# STM32G0B0VET6 register map
File version: 1.0
Registers are 32-bit, access not given, reset 0x0 unless marked. A register's access mark holds for its fields unless they carry their own. Offsets are from the block's base; [hi:lo] are bit positions; {n}, {i} and the like mark numbered series; 'fields as' and 'values as' point back to an identical list.

## DBG
Base 0x40015800
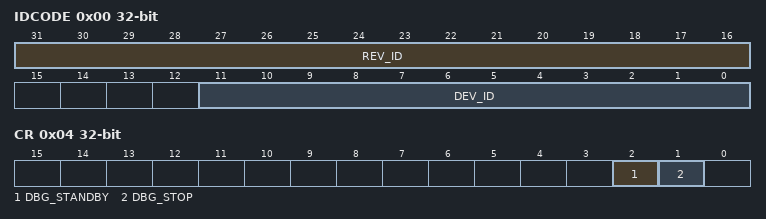
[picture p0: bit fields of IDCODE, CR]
0x00 IDCODE
  [31:16] REV_ID, [11:0] DEV_ID
0x04 CR
  [2] DBG_STANDBY, [1] DBG_STOP
0x08 APBFZ1
0x0C APBFZ2

## DMA1
Base 0x40020000
Same registers: DMA2 0x40020400
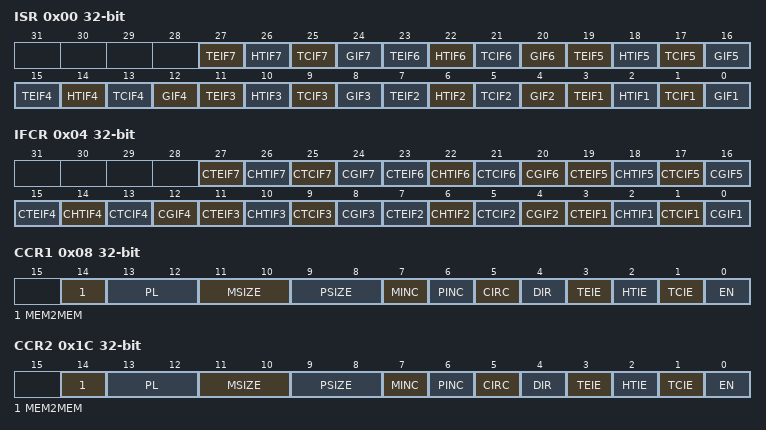
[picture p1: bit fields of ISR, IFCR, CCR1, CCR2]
0x00 ISR
  [4n-1] TEIF{n} (n=1..7), [4n-2] HTIF{n} (n=1..7), [4n-3] TCIF{n} (n=1..7), [4n-4] GIF{n} (n=1..7)
0x04 IFCR
  [4n-1] CTEIF{n} (n=1..7), [4n-2] CHTIF{n} (n=1..7), [4n-3] CTCIF{n} (n=1..7), [4n-4] CGIF{n} (n=1..7)
0x08 CCR1
  [14] MEM2MEM, [13:12] PL, [11:10] MSIZE, [9:8] PSIZE, [7] MINC, [6] PINC, [5] CIRC, [4] DIR, [3] TEIE, [2] HTIE, [1] TCIE, [0] EN
0x0C CNDTR1
  [15:0] NDT
0x10 CPAR1
  [31:0] PA
{0x0+0x14*i} CMAR{i} (i=1..7)
  [31:0] MA
0x1C CCR2
  fields as CCR1
0x20 CNDTR2
  [15:0] NDT
0x24 CPAR2
  [31:0] PA
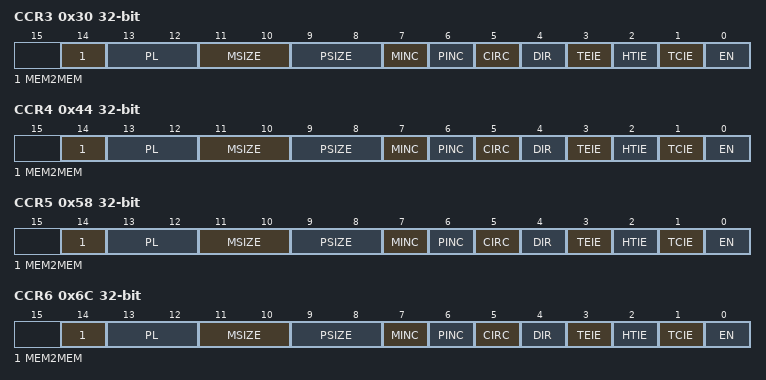
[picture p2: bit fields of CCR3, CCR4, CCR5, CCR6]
0x30 CCR3
  fields as CCR1
0x34 CNDTR3
  [15:0] NDT
0x38 CPAR3
  [31:0] PA
0x44 CCR4
  fields as CCR1
0x48 CNDTR4
  [15:0] NDT
0x4C CPAR4
  [31:0] PA
0x58 CCR5
  fields as CCR1
0x5C CNDTR5
  [15:0] NDT
0x60 CPAR5
  [31:0] PA
0x6C CCR6
  fields as CCR1
0x70 CNDTR6
  [15:0] NDT
0x74 CPAR6
  [31:0] PA
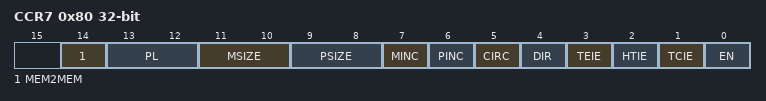
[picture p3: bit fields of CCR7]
0x80 CCR7
  fields as CCR1
0x84 CNDTR7
  [15:0] NDT
0x88 CPAR7
  [31:0] PA

## DMAMUX1
Base 0x40020800
0x00 CCR0
0x04 CCR1
0x08 CCR2
0x0C CCR3
{0x0+4i} CCR{i} (i=4..9)
0x28 CCR0
0x2C CCR1
0x80 CCRs
0x100 CCR0
0x104 CCR1
0x108 CCR2
0x10C CCR3
0x140 CCRs

## RCC
Base 0x40021000
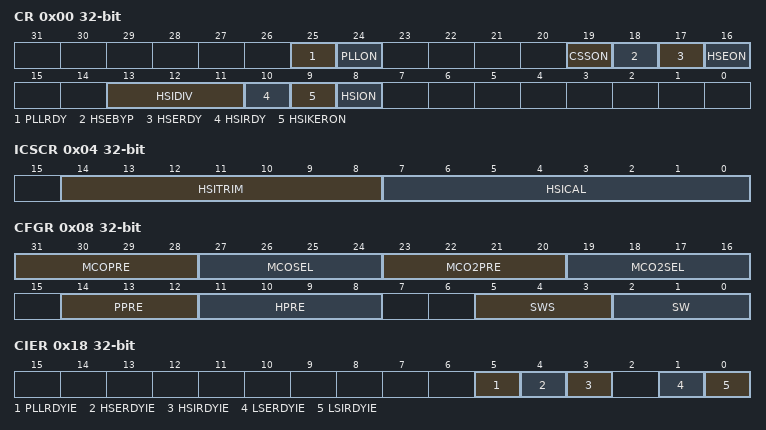
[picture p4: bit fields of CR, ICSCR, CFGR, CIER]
0x00 CR
  [25] PLLRDY, [24] PLLON, [19] CSSON, [18] HSEBYP, [17] HSERDY, [16] HSEON, [13:11] HSIDIV, [10] HSIRDY, [9] HSIKERON, [8] HSION
0x04 ICSCR
  [14:8] HSITRIM, [7:0] HSICAL
0x08 CFGR
  [31:28] MCOPRE, [27:24] MCOSEL, [23:20] MCO2PRE, [19:16] MCO2SEL, [14:12] PPRE, [11:8] HPRE, [5:3] SWS, [2:0] SW
0x0C PLLCFGR
  [31:29] PLLR, [28] PLLREN, [27:25] PLLQ, [24] PLLQEN, [21:17] PLLP, [16] PLLPEN, [14:8] PLLN, [6:4] PLLM, [1] PLLSRC_HSI, [1:0] PLLSRC_HSE
0x14 CRRCR
0x18 CIER
  [5] PLLRDYIE, [4] HSERDYIE, [3] HSIRDYIE, [1] LSERDYIE, [0] LSIRDYIE
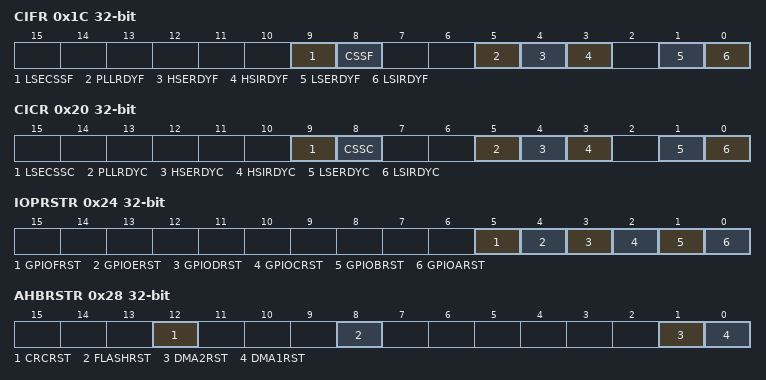
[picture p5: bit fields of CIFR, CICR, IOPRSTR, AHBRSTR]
0x1C CIFR
  [9] LSECSSF, [8] CSSF, [5] PLLRDYF, [4] HSERDYF, [3] HSIRDYF, [1] LSERDYF, [0] LSIRDYF
0x20 CICR
  [9] LSECSSC, [8] CSSC, [5] PLLRDYC, [4] HSERDYC, [3] HSIRDYC, [1] LSERDYC, [0] LSIRDYC
0x24 IOPRSTR
  [5] GPIOFRST, [4] GPIOERST, [3] GPIODRST, [2] GPIOCRST, [1] GPIOBRST, [0] GPIOARST
0x28 AHBRSTR
  [12] CRCRST, [8] FLASHRST, [1] DMA2RST, [0] DMA1RST
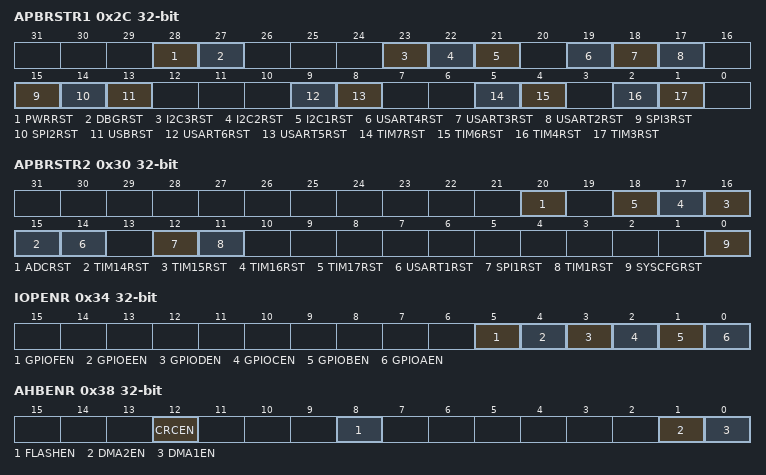
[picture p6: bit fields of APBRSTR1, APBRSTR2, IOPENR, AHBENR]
0x2C APBRSTR1
  [28] PWRRST, [27] DBGRST, [23] I2C3RST, [22] I2C2RST, [21] I2C1RST, [19] USART4RST, [18] USART3RST, [17] USART2RST, [15] SPI3RST, [14] SPI2RST, [13] USBRST, [9] USART6RST, [8] USART5RST, [5] TIM7RST, [4] TIM6RST, [2] TIM4RST, [1] TIM3RST
0x30 APBRSTR2
  [20] ADCRST, [n+1] TIM{n}RST (n=14..17), [14] USART1RST, [12] SPI1RST, [11] TIM1RST, [0] SYSCFGRST
0x34 IOPENR
  [5] GPIOFEN, [4] GPIOEEN, [3] GPIODEN, [2] GPIOCEN, [1] GPIOBEN, [0] GPIOAEN
0x38 AHBENR
  [12] CRCEN, [8] FLASHEN, [1] DMA2EN, [0] DMA1EN
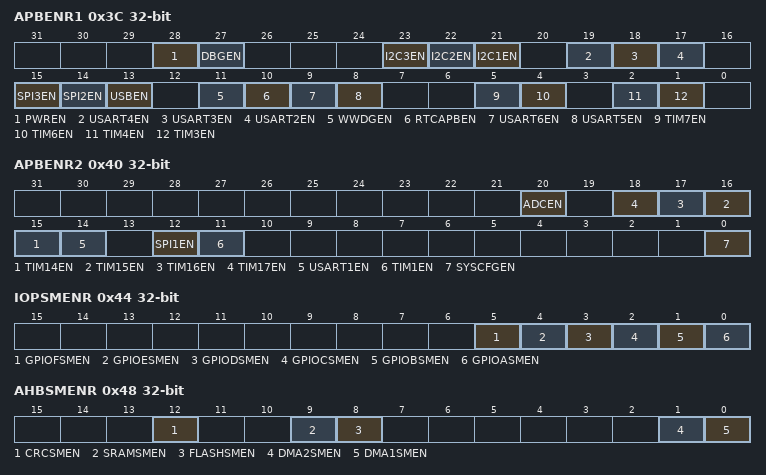
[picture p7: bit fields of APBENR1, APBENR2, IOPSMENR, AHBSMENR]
0x3C APBENR1
  [28] PWREN, [27] DBGEN, [23] I2C3EN, [22] I2C2EN, [21] I2C1EN, [19] USART4EN, [18] USART3EN, [17] USART2EN, [15] SPI3EN, [14] SPI2EN, [13] USBEN, [11] WWDGEN, [10] RTCAPBEN, [9] USART6EN, [8] USART5EN, [5] TIM7EN, [4] TIM6EN, [2] TIM4EN, [1] TIM3EN
0x40 APBENR2
  [20] ADCEN, [n+1] TIM{n}EN (n=14..17), [14] USART1EN, [12] SPI1EN, [11] TIM1EN, [0] SYSCFGEN
0x44 IOPSMENR
  [5] GPIOFSMEN, [4] GPIOESMEN, [3] GPIODSMEN, [2] GPIOCSMEN, [1] GPIOBSMEN, [0] GPIOASMEN
0x48 AHBSMENR
  [12] CRCSMEN, [9] SRAMSMEN, [8] FLASHSMEN, [1] DMA2SMEN, [0] DMA1SMEN
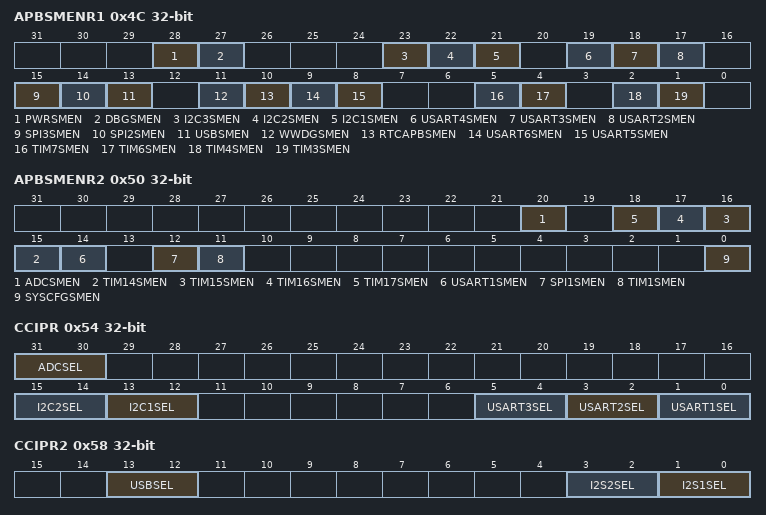
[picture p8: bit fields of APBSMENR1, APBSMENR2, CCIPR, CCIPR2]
0x4C APBSMENR1
  [28] PWRSMEN, [27] DBGSMEN, [23] I2C3SMEN, [22] I2C2SMEN, [21] I2C1SMEN, [19] USART4SMEN, [18] USART3SMEN, [17] USART2SMEN, [15] SPI3SMEN, [14] SPI2SMEN, [13] USBSMEN, [11] WWDGSMEN, [10] RTCAPBSMEN, [9] USART6SMEN, [8] USART5SMEN, [5] TIM7SMEN, [4] TIM6SMEN, [2] TIM4SMEN, [1] TIM3SMEN
0x50 APBSMENR2
  [20] ADCSMEN, [n+1] TIM{n}SMEN (n=14..17), [14] USART1SMEN, [12] SPI1SMEN, [11] TIM1SMEN, [0] SYSCFGSMEN
0x54 CCIPR
  [31:30] ADCSEL, [15:14] I2C2SEL, [13:12] I2C1SEL, [5:4] USART3SEL, [3:2] USART2SEL, [1:0] USART1SEL
0x58 CCIPR2
  [13:12] USBSEL, [3:2] I2S2SEL, [1:0] I2S1SEL
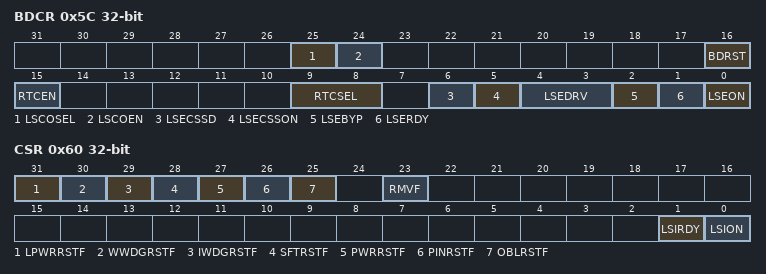
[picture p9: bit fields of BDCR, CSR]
0x5C BDCR
  [25] LSCOSEL, [24] LSCOEN, [16] BDRST, [15] RTCEN, [9:8] RTCSEL, [6] LSECSSD, [5] LSECSSON, [4:3] LSEDRV, [2] LSEBYP, [1] LSERDY, [0] LSEON
0x60 CSR
  [31] LPWRRSTF, [30] WWDGRSTF, [29] IWDGRSTF, [28] SFTRSTF, [27] PWRRSTF, [26] PINRSTF, [25] OBLRSTF, [23] RMVF, [1] LSIRDY, [0] LSION

## EXTI
Base 0x40021800
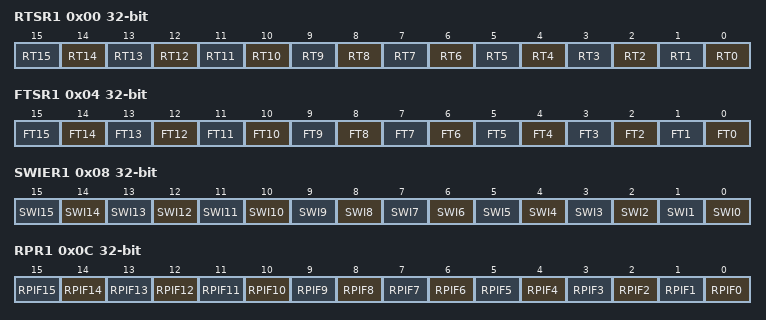
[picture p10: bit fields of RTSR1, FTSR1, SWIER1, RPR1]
0x00 RTSR1
  [n] RT{n} (n=0..15)
0x04 FTSR1
  [n] FT{n} (n=0..15)
0x08 SWIER1
  [n] SWI{n} (n=0..15)
0x0C RPR1
  [n] RPIF{n} (n=0..15)
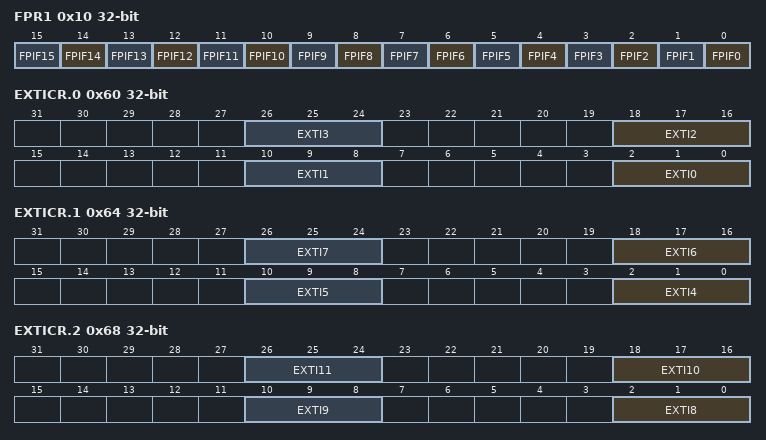
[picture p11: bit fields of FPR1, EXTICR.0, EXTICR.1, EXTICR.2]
0x10 FPR1
  [n] FPIF{n} (n=0..15)
0x60 EXTICR.0
  [8n+2:8n] EXTI{n} (n=0..3)
0x64 EXTICR.1
  [8n-30:8n-32] EXTI{n} (n=4..7)
0x68 EXTICR.2
  [8n-62:8n-64] EXTI{n} (n=8..11)
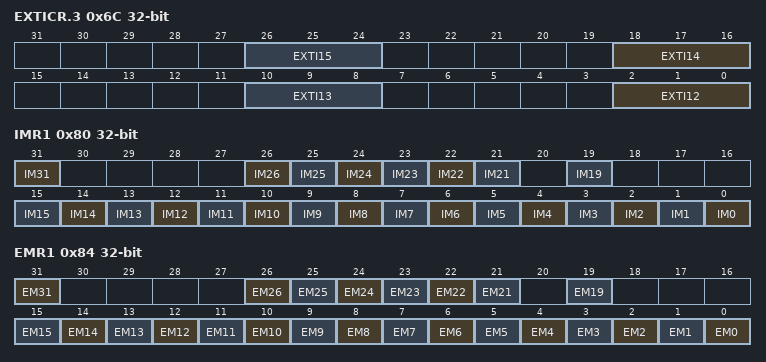
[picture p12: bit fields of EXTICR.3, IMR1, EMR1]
0x6C EXTICR.3
  [8n-94:8n-96] EXTI{n} (n=12..15)
0x80 IMR1
  [31] IM31, [n] IM{n} (n=21..26), [19] IM19, [n] IM{n} (n=0..15)
0x84 EMR1
  [31] EM31, [n] EM{n} (n=21..26), [19] EM19, [n] EM{n} (n=0..15)
0x90 IMR2
  [4] IM36, [4:0] IM
0x94 EMR2
  [4] EM36

## FLASH
Base 0x40022000
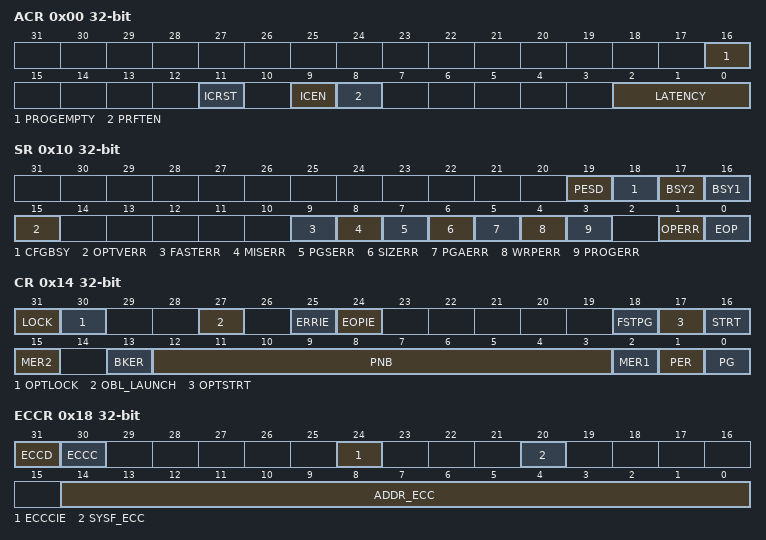
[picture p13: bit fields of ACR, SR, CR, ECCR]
0x00 ACR
  [16] PROGEMPTY, [11] ICRST, [9] ICEN, [8] PRFTEN, [2:0] LATENCY
0x08 KEYR
0x0C OPTKEYR
0x10 SR
  [19] PESD, [18] CFGBSY, [17] BSY2, [16] BSY1, [15] OPTVERR, [9] FASTERR, [8] MISERR, [7] PGSERR, [6] SIZERR, [5] PGAERR, [4] WRPERR, [3] PROGERR, [1] OPERR, [0] EOP
0x14 CR
  [31] LOCK, [30] OPTLOCK, [27] OBL_LAUNCH, [25] ERRIE, [24] EOPIE, [18] FSTPG, [17] OPTSTRT, [16] STRT, [15] MER2, [13] BKER, [12:3] PNB, [2] MER1, [1] PER, [0] PG
0x18 ECCR
  [31] ECCD, [30] ECCC, [24] ECCCIE, [20] SYSF_ECC, [14:0] ADDR_ECC
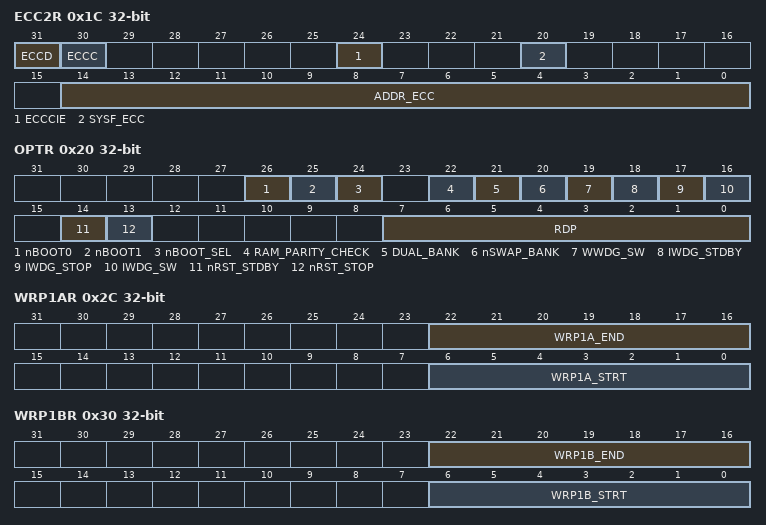
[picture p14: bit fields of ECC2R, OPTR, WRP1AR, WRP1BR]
0x1C ECC2R
  [31] ECCD, [30] ECCC, [24] ECCCIE, [20] SYSF_ECC, [14:0] ADDR_ECC
0x20 OPTR
  [26] nBOOT0, [25] nBOOT1, [24] nBOOT_SEL, [22] RAM_PARITY_CHECK, [21] DUAL_BANK, [20] nSWAP_BANK, [19] WWDG_SW, [18] IWDG_STDBY, [17] IWDG_STOP, [16] IWDG_SW, [14] nRST_STDBY, [13] nRST_STOP, [7:0] RDP
0x2C WRP1AR
  [22:16] WRP1A_END, [6:0] WRP1A_STRT
0x30 WRP1BR
  [22:16] WRP1B_END, [6:0] WRP1B_STRT
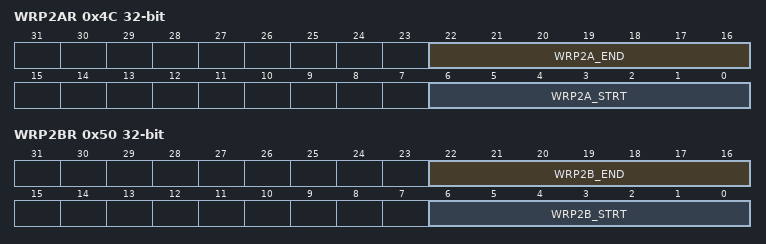
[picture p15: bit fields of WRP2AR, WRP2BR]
0x4C WRP2AR
  [22:16] WRP2A_END, [6:0] WRP2A_STRT
0x50 WRP2BR
  [22:16] WRP2B_END, [6:0] WRP2B_STRT

## CRC
Base 0x40023000
0x00 DR
0x04 IDR
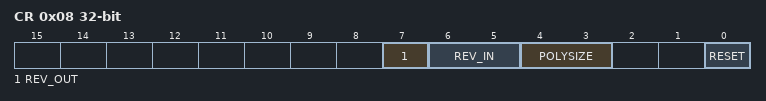
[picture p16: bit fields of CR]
0x08 CR
  [7] REV_OUT, [6:5] REV_IN, [4:3] POLYSIZE, [0] RESET
0x10 INIT
0x14 POL

## GPIOA
Base 0x50000000
Same registers: GPIOB 0x50000400, GPIOC 0x50000800, GPIOD 0x50000C00, GPIOE 0x50001000, GPIOF 0x50001400
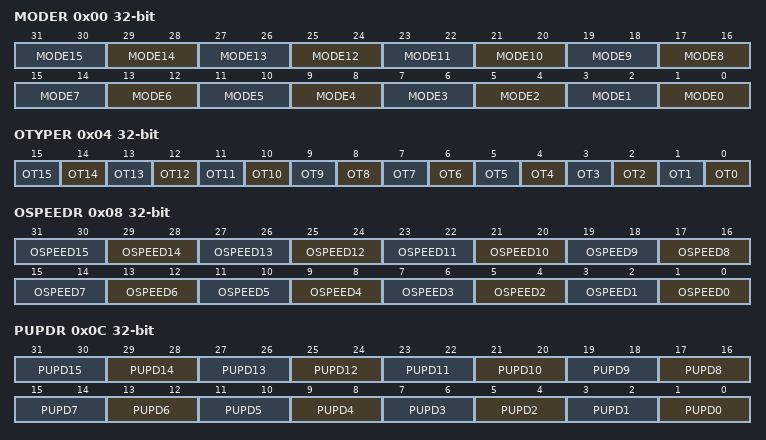
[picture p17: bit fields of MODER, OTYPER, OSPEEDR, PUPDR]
0x00 MODER
  [2n+1:2n] MODE{n} (n=0..15)
0x04 OTYPER
  [n] OT{n} (n=0..15)
0x08 OSPEEDR
  [2n+1:2n] OSPEED{n} (n=0..15)
0x0C PUPDR
  [2n+1:2n] PUPD{n} (n=0..15)
0x10 IDR
  [n] ID{n} (n=0..15)
0x14 ODR
  [n] OD{n} (n=0..15)
0x18 BSRR
  [n+16] BR{n} (n=0..15), [n] BS{n} (n=0..15)
0x1C LCKR
  [16] LCKK, [n] LCK{n} (n=0..15)
0x20 AFR.0
  [4n+3:4n] AFSEL{n} (n=0..7)
0x24 AFR.1
  [4n-29:4n-32] AFSEL{n} (n=8..15)
0x28 BRR
  [n] BR{n} (n=0..15)
